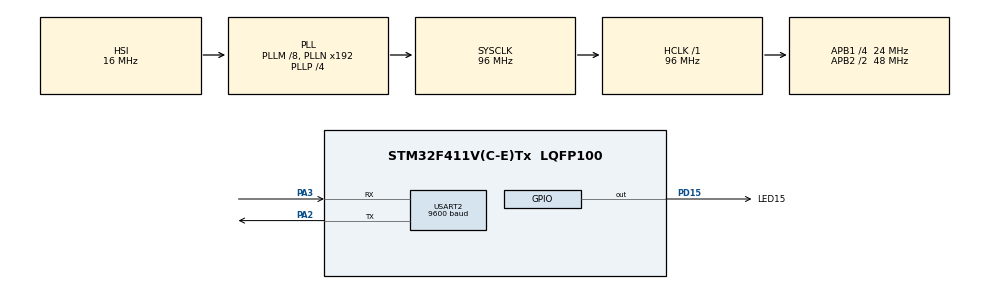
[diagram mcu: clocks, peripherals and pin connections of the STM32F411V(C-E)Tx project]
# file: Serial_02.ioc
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Mcu.Family=STM32F4
Mcu.Name=STM32F411V(C-E)Tx
Mcu.Package=LQFP100
NVIC.PriorityGroup=NVIC_PRIORITYGROUP_0
PA2.Mode=Asynchronous
PA2.Signal=USART2_TX
PA3.Mode=Asynchronous
PA3.Signal=USART2_RX
PD15.GPIO_Label=LED15
PD15.Signal=GPIO_Output
PH0\ -\ OSC_IN.Mode=HSE-External-Oscillator
PH0\ -\ OSC_IN.Signal=RCC_OSC_IN
PH1\ -\ OSC_OUT.Mode=HSE-External-Oscillator
PH1\ -\ OSC_OUT.Signal=RCC_OSC_OUT
ProjectManager.HeapSize=0x200
ProjectManager.StackSize=0x400
ProjectManager.TargetToolchain=STM32CubeIDE
RCC.48MHZClocksFreq_Value=48000000
RCC.AHBFreq_Value=96000000
RCC.APB1CLKDivider=RCC_HCLK_DIV4
RCC.APB1Freq_Value=24000000
RCC.APB1TimFreq_Value=48000000
RCC.APB2CLKDivider=RCC_HCLK_DIV2
RCC.APB2Freq_Value=48000000
RCC.APB2TimFreq_Value=96000000
RCC.CortexFreq_Value=96000000
RCC.HCLKFreq_Value=96000000
RCC.HSE_VALUE=8000000
RCC.HSI_VALUE=16000000
RCC.LSE_VALUE=32768
RCC.PLLI2SM=5
RCC.PLLI2SN=200
RCC.PLLM=8
RCC.PLLP=RCC_PLLP_DIV4
RCC.PLLQ=8
RCC.SYSCLKFreq_VALUE=96000000
RCC.SYSCLKSource=RCC_SYSCLKSOURCE_PLLCLK
RCC.VCOOutputFreq_Value=384000000
USART2.BaudRate=9600
USART2.VirtualMode=VM_ASYNC
board=STM32F411E-DISCO

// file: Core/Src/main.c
/* USER CODE BEGIN Header */
/**
  ******************************************************************************
  * @file           : main.c
  * @brief          : Main program body
  ******************************************************************************
  * @attention
  *
  * Copyright (c) 2024 STMicroelectronics.
  * All rights reserved.
  *
  * This software is licensed under terms that can be found in the LICENSE file
  * in the root directory of this software component.
  * If no LICENSE file comes with this software, it is provided AS-IS.
  *
  ******************************************************************************
  */
/* USER CODE END Header */
#include "main.h"

UART_HandleTypeDef huart2;

void SystemClock_Config(void);
static void MX_GPIO_Init(void);
static void MX_USART2_UART_Init(void);

/* USER CODE BEGIN 0 */
uint32_t number1=1;
uint32_t count=5;
uint32_t count1;
uint32_t count2;
uint32_t table=0;

/* USER CODE END 0 */

int main(void)
{

  /* MCU Configuration--------------------------------------------------------*/

  /* Reset of all peripherals, Initializes the Flash interface and the Systick. */
  HAL_Init();

  /* Configure the system clock */
  SystemClock_Config();

  /* Initialize all configured peripherals */
  MX_GPIO_Init();
  MX_USART2_UART_Init();
  /* USER CODE BEGIN 2 */

RCC->AHB1ENR |=(1<<3);

GPIOD->MODER |=(1<<30);
GPIOD->MODER &=~(1<<31);
GPIOD->OTYPER &=~(1<<15);
GPIOD->OSPEEDR &=~(1<<30);
GPIOD->OSPEEDR &=~(1<<31);
GPIOD->PUPDR &=~(1<<30);
GPIOD->PUPDR &=~(1<<31);

GPIOD->MODER |=(1<<28);
GPIOD->MODER &=~(1<<29);
GPIOD->OTYPER &=~(1<<14);
GPIOD->OSPEEDR &=~(1<<28);
GPIOD->OSPEEDR &=~(1<<29);
GPIOD->PUPDR &=~(1<<28);
GPIOD->PUPDR &=~(1<<29);

GPIOD->MODER |=(1<<26);
GPIOD->MODER &=~(1<<27);
GPIOD->OTYPER &=~(1<<13);
GPIOD->OSPEEDR &=~(1<<26);
GPIOD->OSPEEDR &=~(1<<27);
GPIOD->PUPDR &=~(1<<26);
GPIOD->PUPDR &=~(1<<27);

GPIOD->MODER |=(1<<24);
GPIOD->MODER &=~(1<<25);
GPIOD->OTYPER &=~(1<<12);
GPIOD->OSPEEDR &=~(1<<24);
GPIOD->OSPEEDR &=~(1<<25);
GPIOD->PUPDR &=~(1<<24);
GPIOD->PUPDR &=~(1<<25);

GPIOD->ODR |=(1<<15);
GPIOD->ODR |=(1<<14);
GPIOD->ODR |=(1<<13);
GPIOD->ODR |=(1<<12);

number1=GPIOD->ODR;
count=number1;
count1=number1;
count=count & (1<<15);
count1=count1 & (1<<14);
count2=GPIOD->ODR & (1<<13);
uint8_t data_tx[]="selam";
uint8_t data_tx1[100];

for (int j = 0;  j < 100; ++ j) {
	data_tx1[j]='B';
	HAL_Delay(10);
}

//int length = sizeof(carName) / sizeof(carName[0]);
int length=sizeof(data_tx1) / sizeof(data_tx1[0]);
//number1=(GPIOD->ODR & (1<<15));

  /* USER CODE END 2 */

  /* Infinite loop */
	while (1) {

    /* USER CODE BEGIN 3 */
		//USART2->DR = data_tx[0];
		//USART2->DR ='5';
		//HAL_Delay(1000);
		//USART2->DR='A';
		for (int i = 0; i <100; ++i) {
			USART2->DR = data_tx1[i];
			HAL_Delay(1000);
			USART2->DR = '\n';
			HAL_Delay(10);
		}

		//number1=GPIOD->ODR & GPIO_ODR_ODR_15;
		// GPIOD->ODR |=(1<<14);
		//GPIOD->ODR &=~(1<<15);
		/*HAL_Delay(3000);
		if (count == 32768) {
			GPIOD->ODR &= ~(1 << 15);
		}

		HAL_Delay(3000);
		if (count1 == 16384) {
			GPIOD->ODR &= ~(1 << 14);
		}

		HAL_Delay(3000);
				if (count2 == 8192) {
					GPIOD->ODR &= ~(1 << 13);
				}*/
	}
  /* USER CODE END 3 */
}

void SystemClock_Config(void)
{
  RCC_OscInitTypeDef RCC_OscInitStruct = {0};
  RCC_ClkInitTypeDef RCC_ClkInitStruct = {0};

  /** Configure the main internal regulator output voltage
  */
  __HAL_RCC_PWR_CLK_ENABLE();
  __HAL_PWR_VOLTAGESCALING_CONFIG(PWR_REGULATOR_VOLTAGE_SCALE1);

  /** Initializes the RCC Oscillators according to the specified parameters
  * in the RCC_OscInitTypeDef structure.
  */
  RCC_OscInitStruct.OscillatorType = RCC_OSCILLATORTYPE_HSI;
  RCC_OscInitStruct.HSIState = RCC_HSI_ON;
  RCC_OscInitStruct.HSICalibrationValue = RCC_HSICALIBRATION_DEFAULT;
  RCC_OscInitStruct.PLL.PLLState = RCC_PLL_ON;
  RCC_OscInitStruct.PLL.PLLSource = RCC_PLLSOURCE_HSI;
  RCC_OscInitStruct.PLL.PLLM = 8;
  RCC_OscInitStruct.PLL.PLLN = 192;
  RCC_OscInitStruct.PLL.PLLP = RCC_PLLP_DIV4;
  RCC_OscInitStruct.PLL.PLLQ = 8;
  if (HAL_RCC_OscConfig(&RCC_OscInitStruct) != HAL_OK)
  {
    Error_Handler();
  }

  /** Initializes the CPU, AHB and APB buses clocks
  */
  RCC_ClkInitStruct.ClockType = RCC_CLOCKTYPE_HCLK|RCC_CLOCKTYPE_SYSCLK
                              |RCC_CLOCKTYPE_PCLK1|RCC_CLOCKTYPE_PCLK2;
  RCC_ClkInitStruct.SYSCLKSource = RCC_SYSCLKSOURCE_PLLCLK;
  RCC_ClkInitStruct.AHBCLKDivider = RCC_SYSCLK_DIV1;
  RCC_ClkInitStruct.APB1CLKDivider = RCC_HCLK_DIV4;
  RCC_ClkInitStruct.APB2CLKDivider = RCC_HCLK_DIV2;

  if (HAL_RCC_ClockConfig(&RCC_ClkInitStruct, FLASH_LATENCY_3) != HAL_OK)
  {
    Error_Handler();
  }
}

static void MX_USART2_UART_Init(void)
{

  huart2.Instance = USART2;
  huart2.Init.BaudRate = 9600;
  huart2.Init.WordLength = UART_WORDLENGTH_8B;
  huart2.Init.StopBits = UART_STOPBITS_1;
  huart2.Init.Parity = UART_PARITY_NONE;
  huart2.Init.Mode = UART_MODE_TX_RX;
  huart2.Init.HwFlowCtl = UART_HWCONTROL_NONE;
  huart2.Init.OverSampling = UART_OVERSAMPLING_16;
  if (HAL_UART_Init(&huart2) != HAL_OK)
  {
    Error_Handler();
  }

}

static void MX_GPIO_Init(void)
{
  GPIO_InitTypeDef GPIO_InitStruct = {0};

  /* GPIO Ports Clock Enable */
  __HAL_RCC_GPIOH_CLK_ENABLE();
  __HAL_RCC_GPIOA_CLK_ENABLE();
  __HAL_RCC_GPIOD_CLK_ENABLE();

  /*Configure GPIO pin Output Level */
  HAL_GPIO_WritePin(LED15_GPIO_Port, LED15_Pin, GPIO_PIN_RESET);

  /*Configure GPIO pin : LED15_Pin */
  GPIO_InitStruct.Pin = LED15_Pin;
  GPIO_InitStruct.Mode = GPIO_MODE_OUTPUT_PP;
  GPIO_InitStruct.Pull = GPIO_NOPULL;
  GPIO_InitStruct.Speed = GPIO_SPEED_FREQ_LOW;
  HAL_GPIO_Init(LED15_GPIO_Port, &GPIO_InitStruct);

}

void Error_Handler(void)
{
  __disable_irq();
  while (1)
  {
  }
}
